# ioam3358 register map
Registers are 32-bit, access not given, no defined reset value unless marked. A register's access mark holds for its fields unless they carry their own. Addresses are absolute; registers are grouped by the start of their names; [hi:lo] are bit positions; {n}, {i} and the like mark numbered series; 'fields as' and 'values as' point back to an identical list.

## SFR
0x44E00B00 REVISION_PRM
  [7:0] REV
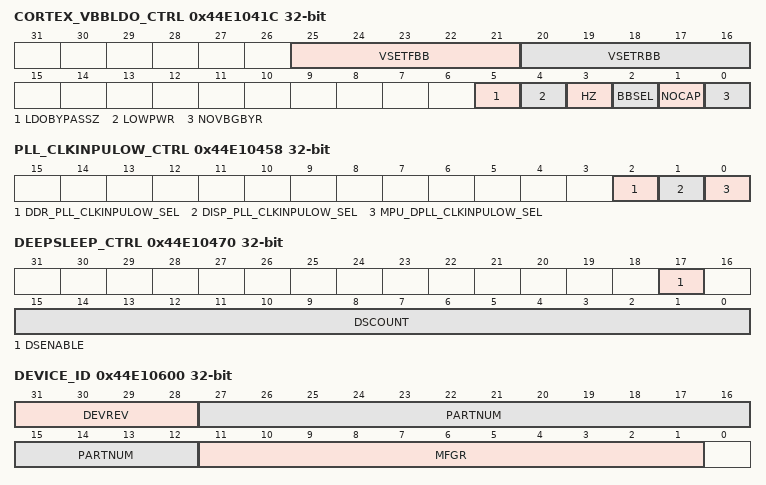
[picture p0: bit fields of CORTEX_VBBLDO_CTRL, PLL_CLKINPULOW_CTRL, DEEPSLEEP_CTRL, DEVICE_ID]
0x44E1041C CORTEX_VBBLDO_CTRL
  [25:21] VSETFBB, [20:16] VSETRBB, [5] LDOBYPASSZ, [4] LOWPWR, [3] HZ, [2] BBSEL, [1] NOCAP, [0] NOVBGBYR
0x44E10428 CORE_SLDO_CTRL
  [25:16] vset
0x44E1042C MPU_SLDO_CTRL
  [25:16] vset
0x44E10444 CLK32KDIVRATIO_CTRL
  [0] CLKDIVOPP50_EN
0x44E10458 PLL_CLKINPULOW_CTRL
  [2] DDR_PLL_CLKINPULOW_SEL, [1] DISP_PLL_CLKINPULOW_SEL, [0] MPU_DPLL_CLKINPULOW_SEL
0x44E10468 MOSC_CTRL
  [0] RESSELECT
0x44E1046C RCOSC_CTRL
  [0] STOPOSC
0x44E10470 DEEPSLEEP_CTRL
  [17] DSENABLE, [15:0] DSCOUNT
0x44E10600 DEVICE_ID
  [31:28] DEVREV, [27:12] PARTNUM, [11:1] MFGR
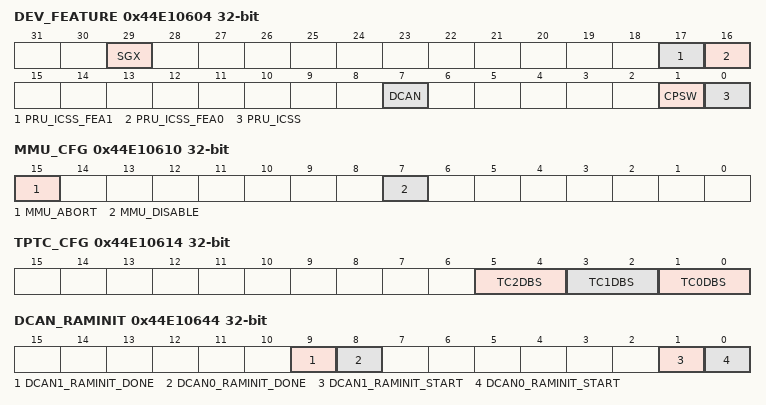
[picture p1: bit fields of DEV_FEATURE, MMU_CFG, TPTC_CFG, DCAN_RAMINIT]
0x44E10604 DEV_FEATURE
  [29] SGX, [17] PRU_ICSS_FEA1, [16] PRU_ICSS_FEA0, [7] DCAN, [1] CPSW, [0] PRU_ICSS
0x44E10610 MMU_CFG
  [15] MMU_ABORT, [7] MMU_DISABLE
0x44E10614 TPTC_CFG
  [5:4] TC2DBS, [3:2] TC1DBS, [1:0] TC0DBS
0x44E10644 DCAN_RAMINIT
  [9] DCAN1_RAMINIT_DONE, [8] DCAN0_RAMINIT_DONE, [1] DCAN1_RAMINIT_START, [0] DCAN0_RAMINIT_START
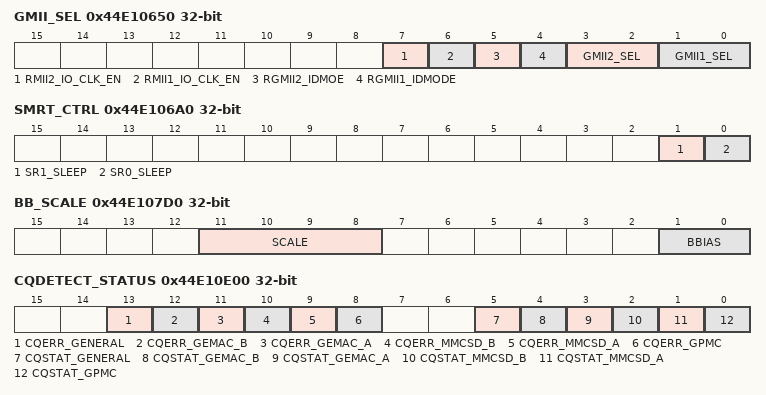
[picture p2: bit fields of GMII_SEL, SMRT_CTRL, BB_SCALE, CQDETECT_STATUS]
0x44E10650 GMII_SEL
  [7] RMII2_IO_CLK_EN, [6] RMII1_IO_CLK_EN, [5] RGMII2_IDMOE, [4] RGMII1_IDMODE, [3:2] GMII2_SEL, [1:0] GMII1_SEL
0x44E106A0 SMRT_CTRL
  [1] SR1_SLEEP, [0] SR0_SLEEP
0x44E107D0 BB_SCALE
  [11:8] SCALE, [1:0] BBIAS
0x44E10E00 CQDETECT_STATUS
  [13] CQERR_GENERAL, [12] CQERR_GEMAC_B, [11] CQERR_GEMAC_A, [10] CQERR_MMCSD_B, [9] CQERR_MMCSD_A, [8] CQERR_GPMC, [5] CQSTAT_GENERAL, [4] CQSTAT_GEMAC_B, [3] CQSTAT_GEMAC_A, [2] CQSTAT_MMCSD_B, [1] CQSTAT_MMCSD_A, [0] CQSTAT_GPMC
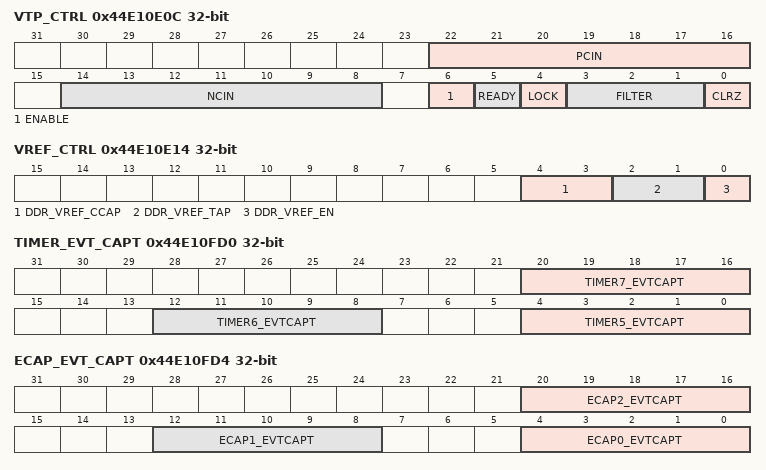
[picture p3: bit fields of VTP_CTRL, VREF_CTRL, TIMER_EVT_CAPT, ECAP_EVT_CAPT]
0x44E10E0C VTP_CTRL
  [22:16] PCIN, [14:8] NCIN, [6] ENABLE, [5] READY, [4] LOCK, [3:1] FILTER, [0] CLRZ
0x44E10E14 VREF_CTRL
  [4:3] DDR_VREF_CCAP, [2:1] DDR_VREF_TAP, [0] DDR_VREF_EN
0x44E10FD0 TIMER_EVT_CAPT
  [20:16] TIMER7_EVTCAPT, [12:8] TIMER6_EVTCAPT, [4:0] TIMER5_EVTCAPT
0x44E10FD4 ECAP_EVT_CAPT
  [20:16] ECAP2_EVTCAPT, [12:8] ECAP1_EVTCAPT, [4:0] ECAP0_EVTCAPT
0x44E10FD8 ADC_EVT_CAPT
  [3:0] ADC_EVTCAPT
0x44E11000 RESET_ISO
  [0] ISO_CONTROL
0x44E11324 M3_TXEV_EOI
  [0] M3_TXEV_EOI
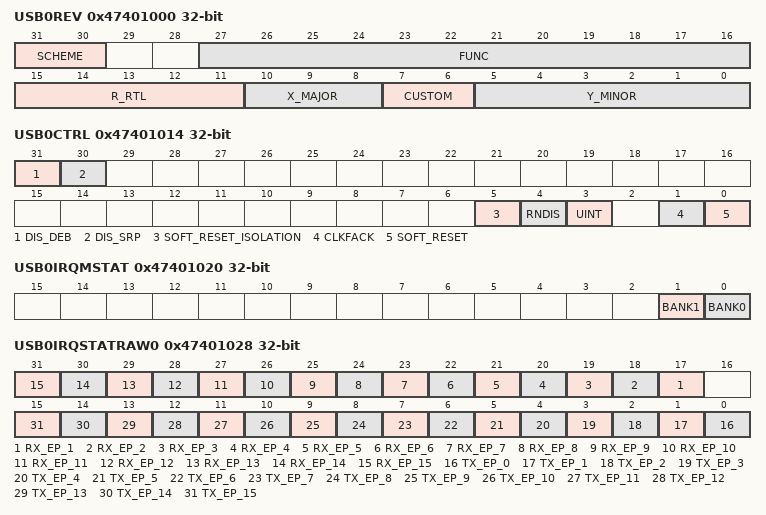
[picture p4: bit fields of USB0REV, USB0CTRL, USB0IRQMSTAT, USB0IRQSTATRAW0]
0x47401000 USB0REV
  [31:30] SCHEME, [27:16] FUNC, [15:11] R_RTL, [10:8] X_MAJOR, [7:6] CUSTOM, [5:0] Y_MINOR
0x47401014 USB0CTRL
  [31] DIS_DEB, [30] DIS_SRP, [5] SOFT_RESET_ISOLATION, [4] RNDIS, [3] UINT, [1] CLKFACK, [0] SOFT_RESET
0x47401018 USB0STAT
  [0] DRVVBUS
0x47401020 USB0IRQMSTAT
  [1] BANK1, [0] BANK0
0x47401024 USB0IRQEOI
  [0] EOI
0x47401028 USB0IRQSTATRAW0
  [n+16] RX_EP_{n} (n=1..15), [n] TX_EP_{n} (n=0..15)
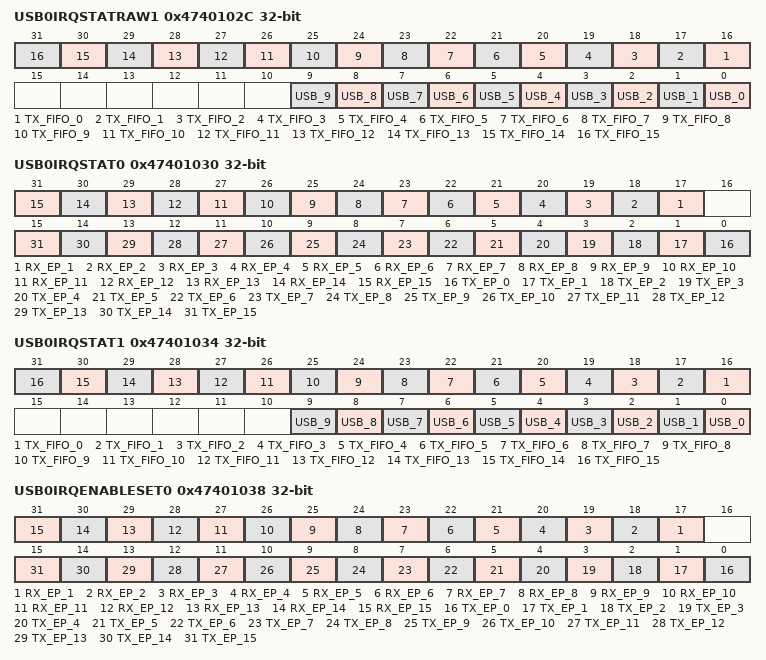
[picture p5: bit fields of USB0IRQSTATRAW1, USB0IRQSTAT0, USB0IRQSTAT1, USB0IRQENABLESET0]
0x4740102C USB0IRQSTATRAW1
  [n+16] TX_FIFO_{n} (n=0..15), [n] USB_{n} (n=0..9)
0x47401030 USB0IRQSTAT0
  [n+16] RX_EP_{n} (n=1..15), [n] TX_EP_{n} (n=0..15)
0x47401034 USB0IRQSTAT1
  [n+16] TX_FIFO_{n} (n=0..15), [n] USB_{n} (n=0..9)
0x47401038 USB0IRQENABLESET0
  [n+16] RX_EP_{n} (n=1..15), [n] TX_EP_{n} (n=0..15)
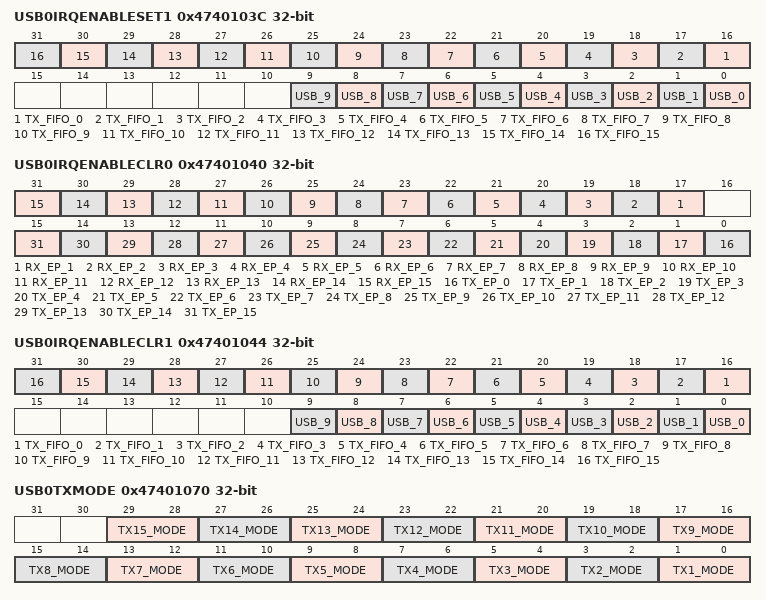
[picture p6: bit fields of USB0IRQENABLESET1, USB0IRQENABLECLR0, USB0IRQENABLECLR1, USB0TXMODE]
0x4740103C USB0IRQENABLESET1
  [n+16] TX_FIFO_{n} (n=0..15), [n] USB_{n} (n=0..9)
0x47401040 USB0IRQENABLECLR0
  [n+16] RX_EP_{n} (n=1..15), [n] TX_EP_{n} (n=0..15)
0x47401044 USB0IRQENABLECLR1
  [n+16] TX_FIFO_{n} (n=0..15), [n] USB_{n} (n=0..9)
0x47401070 USB0TXMODE
  [2n-1:2n-2] TX{n}_MODE (n=1..15)
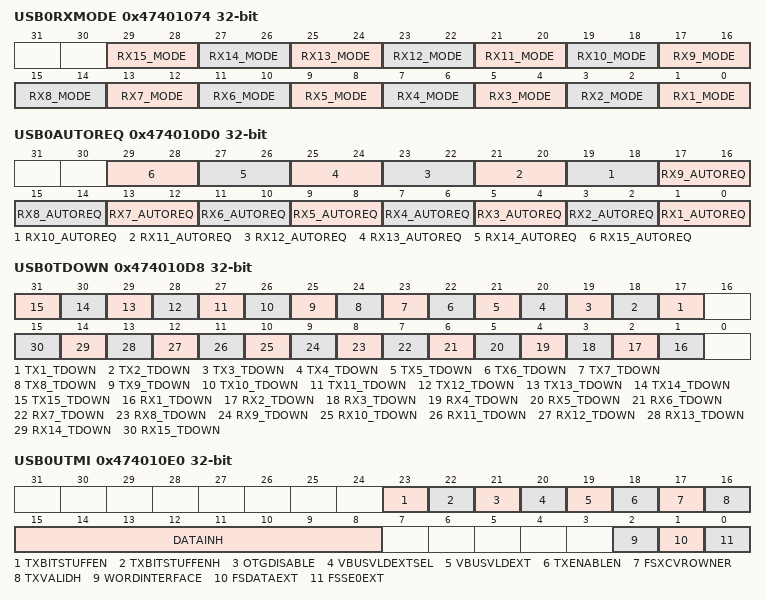
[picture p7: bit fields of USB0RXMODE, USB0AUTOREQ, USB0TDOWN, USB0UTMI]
0x47401074 USB0RXMODE
  [2n-1:2n-2] RX{n}_MODE (n=1..15)
{0x4740107C+4i} USB0GENRNDISEP{i} (i=1..15)
  [15:0] EP{i}_SIZE
0x474010D0 USB0AUTOREQ
  [2n-1:2n-2] RX{n}_AUTOREQ (n=1..15)
0x474010D4 USB0SRPFIXTIME
0x474010D8 USB0TDOWN
  [n+16] TX{n}_TDOWN (n=1..15), [n] RX{n}_TDOWN (n=1..15)
0x474010E0 USB0UTMI
  [23] TXBITSTUFFEN, [22] TXBITSTUFFENH, [21] OTGDISABLE, [20] VBUSVLDEXTSEL, [19] VBUSVLDEXT, [18] TXENABLEN, [17] FSXCVROWNER, [16] TXVALIDH, [15:8] DATAINH, [2] WORDINTERFACE, [1] FSDATAEXT, [0] FSSE0EXT
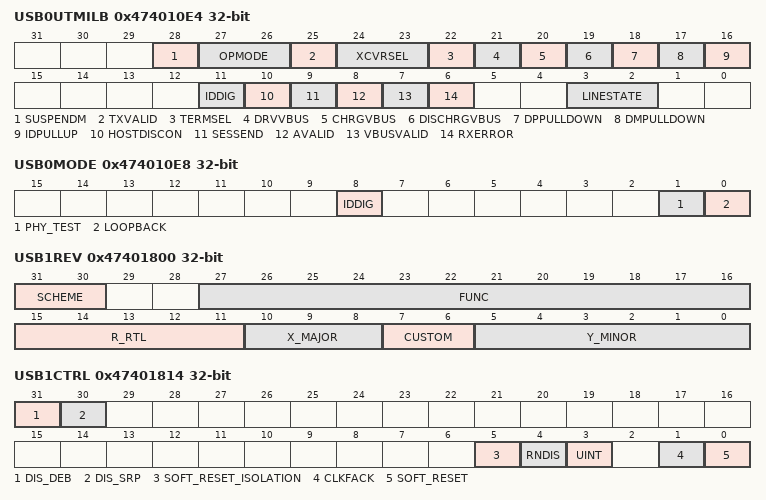
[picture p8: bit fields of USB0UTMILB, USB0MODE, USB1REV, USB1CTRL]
0x474010E4 USB0UTMILB
  [28] SUSPENDM, [27:26] OPMODE, [25] TXVALID, [24:23] XCVRSEL, [22] TERMSEL, [21] DRVVBUS, [20] CHRGVBUS, [19] DISCHRGVBUS, [18] DPPULLDOWN, [17] DMPULLDOWN, [16] IDPULLUP, [11] IDDIG, [10] HOSTDISCON, [9] SESSEND, [8] AVALID, [7] VBUSVALID, [6] RXERROR, [3:2] LINESTATE
0x474010E8 USB0MODE
  [8] IDDIG, [1] PHY_TEST, [0] LOOPBACK
0x47401800 USB1REV
  fields as USB0REV
0x47401814 USB1CTRL
  fields as USB0CTRL
0x47401818 USB1STAT
  [0] DRVVBUS
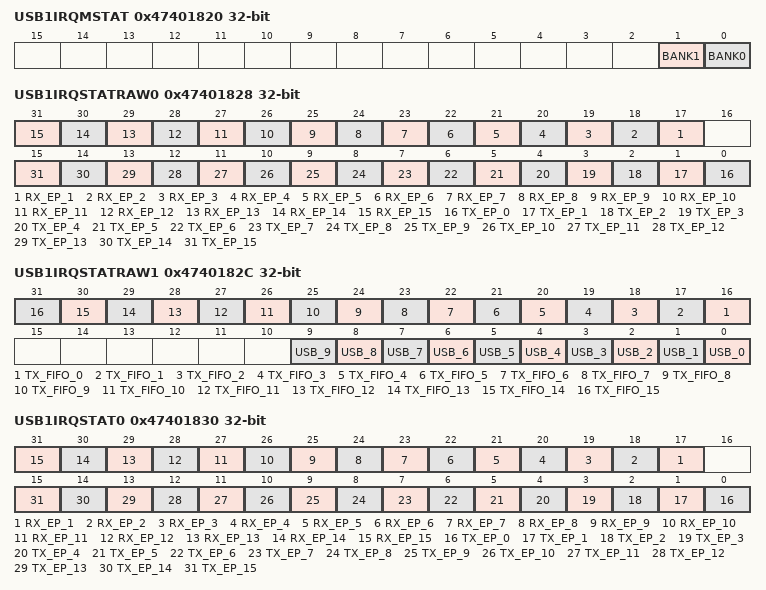
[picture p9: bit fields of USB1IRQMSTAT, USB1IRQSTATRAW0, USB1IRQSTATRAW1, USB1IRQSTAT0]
0x47401820 USB1IRQMSTAT
  [1] BANK1, [0] BANK0
0x47401824 USB1IRQEOI
  [0] EOI
0x47401828 USB1IRQSTATRAW0
  [n+16] RX_EP_{n} (n=1..15), [n] TX_EP_{n} (n=0..15)
0x4740182C USB1IRQSTATRAW1
  [n+16] TX_FIFO_{n} (n=0..15), [n] USB_{n} (n=0..9)
0x47401830 USB1IRQSTAT0
  [n+16] RX_EP_{n} (n=1..15), [n] TX_EP_{n} (n=0..15)
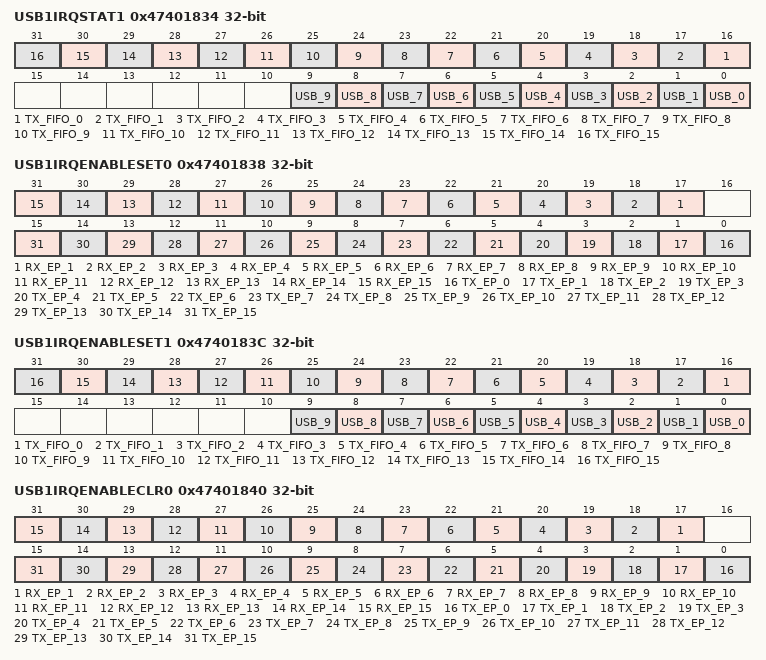
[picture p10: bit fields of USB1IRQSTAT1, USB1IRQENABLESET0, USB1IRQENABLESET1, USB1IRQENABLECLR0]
0x47401834 USB1IRQSTAT1
  [n+16] TX_FIFO_{n} (n=0..15), [n] USB_{n} (n=0..9)
0x47401838 USB1IRQENABLESET0
  [n+16] RX_EP_{n} (n=1..15), [n] TX_EP_{n} (n=0..15)
0x4740183C USB1IRQENABLESET1
  [n+16] TX_FIFO_{n} (n=0..15), [n] USB_{n} (n=0..9)
0x47401840 USB1IRQENABLECLR0
  [n+16] RX_EP_{n} (n=1..15), [n] TX_EP_{n} (n=0..15)
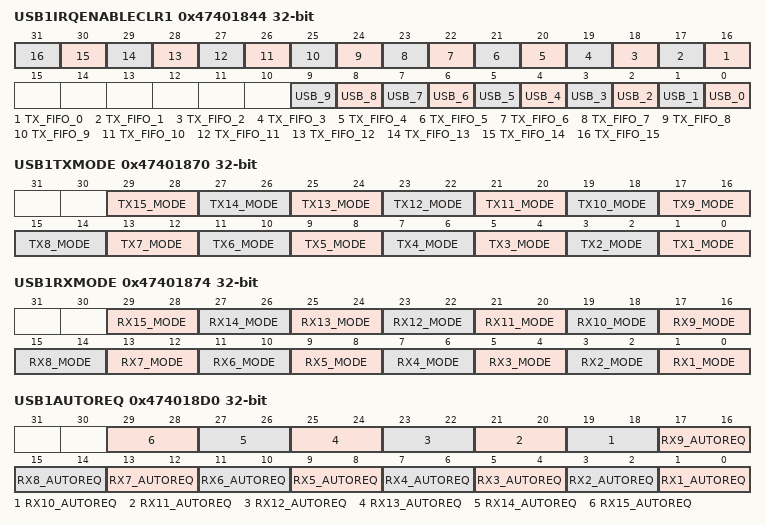
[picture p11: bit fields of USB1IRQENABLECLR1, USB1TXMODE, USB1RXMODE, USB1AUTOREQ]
0x47401844 USB1IRQENABLECLR1
  [n+16] TX_FIFO_{n} (n=0..15), [n] USB_{n} (n=0..9)
0x47401870 USB1TXMODE
  [2n-1:2n-2] TX{n}_MODE (n=1..15)
0x47401874 USB1RXMODE
  [2n-1:2n-2] RX{n}_MODE (n=1..15)
{0x4740187C+4i} USB1GENRNDISEP{i} (i=1..15)
  [15:0] EP{i}_SIZE
0x474018D0 USB1AUTOREQ
  [2n-1:2n-2] RX{n}_AUTOREQ (n=1..15)
0x474018D4 USB1SRPFIXTIME
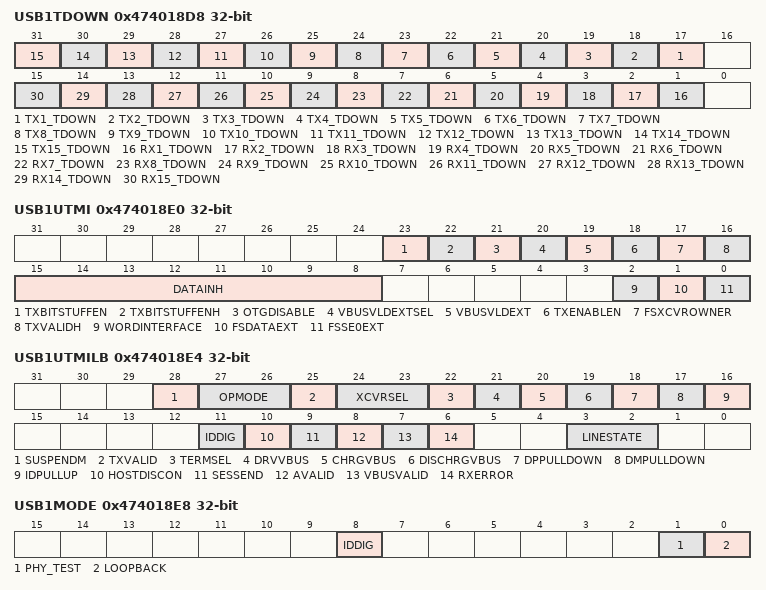
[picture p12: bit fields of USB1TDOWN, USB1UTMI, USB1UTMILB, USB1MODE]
0x474018D8 USB1TDOWN
  [n+16] TX{n}_TDOWN (n=1..15), [n] RX{n}_TDOWN (n=1..15)
0x474018E0 USB1UTMI
  fields as USB0UTMI
0x474018E4 USB1UTMILB
  fields as USB0UTMILB
0x474018E8 USB1MODE
  [8] IDDIG, [1] PHY_TEST, [0] LOOPBACK
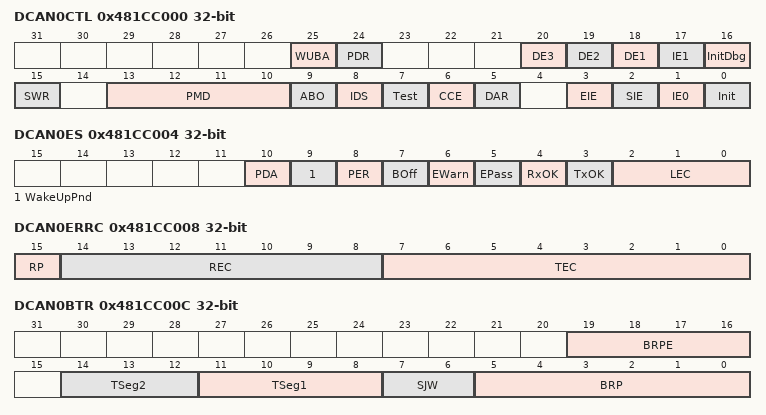
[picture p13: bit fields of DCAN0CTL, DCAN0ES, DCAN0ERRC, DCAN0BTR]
0x481CC000 DCAN0CTL
  [25] WUBA, [24] PDR, [20] DE3, [19] DE2, [18] DE1, [17] IE1, [16] InitDbg, [15] SWR, [13:10] PMD, [9] ABO, [8] IDS, [7] Test, [6] CCE, [5] DAR, [3] EIE, [2] SIE, [1] IE0, [0] Init
0x481CC004 DCAN0ES
  [10] PDA, [9] WakeUpPnd, [8] PER, [7] BOff, [6] EWarn, [5] EPass, [4] RxOK, [3] TxOK, [2:0] LEC
0x481CC004 DCAN0PARITYERR_EOI
0x481CC008 DCAN0ERRC
  [15] RP, [14:8] REC, [7:0] TEC
0x481CC00C DCAN0BTR
  [19:16] BRPE, [14:12] TSeg2, [11:8] TSeg1, [7:6] SJW, [5:0] BRP
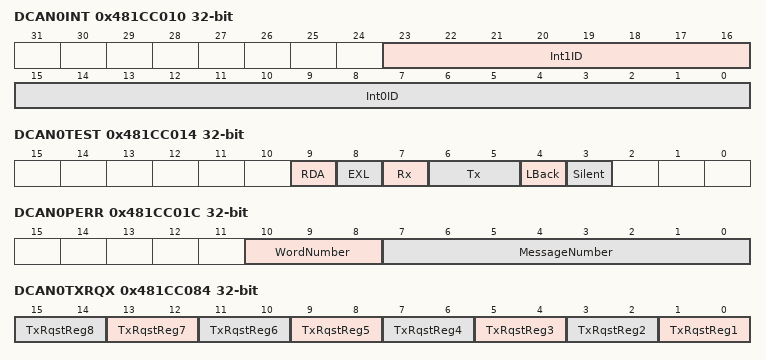
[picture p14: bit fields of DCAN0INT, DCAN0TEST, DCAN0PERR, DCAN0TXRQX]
0x481CC010 DCAN0INT
  [23:16] Int1ID, [15:0] Int0ID
0x481CC014 DCAN0TEST
  [9] RDA, [8] EXL, [7] Rx, [6:5] Tx, [4] LBack, [3] Silent
0x481CC01C DCAN0PERR
  [10:8] WordNumber, [7:0] MessageNumber
0x481CC080 DCAN0ABOTR
0x481CC084 DCAN0TXRQX
  [2n-1:2n-2] TxRqstReg{n} (n=1..8)
0x481CC088 DCAN0TXRQ12
  [n-1] TxRqst{n} (n=1..32)
0x481CC08C DCAN0TXRQ34
  [n-33] TxRqst{n} (n=33..64)
0x481CC090 DCAN0TXRQ56
  [n-65] TxRqst{n} (n=65..96)
0x481CC094 DCAN0TXRQ78
  [n-97] TxRqst{n} (n=97..128)
0x481CC098 DCAN0NWDATX
  [2n-1:2n-2] NewDatReg{n} (n=1..8)
0x481CC09C DCAN0NWDAT12
  [n-1] NewDat{n} (n=1..32)
0x481CC0A0 DCAN0NWDAT34
  [n-33] NewDat{n} (n=33..64)
0x481CC0A4 DCAN0NWDAT56
  [n-65] NewDat{n} (n=65..96)
0x481CC0A8 DCAN0NWDAT78
  [n-97] NewDat{n} (n=97..128)
0x481CC0AC DCAN0INTPNDX
  [2n-1:2n-2] IntPndReg{n} (n=1..8)
0x481CC0B0 DCAN0INTPND12
  [n-1] IntPnd{n} (n=1..32)
0x481CC0B4 DCAN0INTPND34
  [n-33] IntPnd{n} (n=33..64)
0x481CC0B8 DCAN0INTPND56
  [n-65] IntPnd{n} (n=65..96)
0x481CC0BC DCAN0INTPND78
  [n-97] IntPnd{n} (n=97..128)
0x481CC0C0 DCAN0MSGVALX
  [2n-1:2n-2] MsgValReg{n} (n=1..8)
0x481CC0C4 DCAN0MSGVAL12
  [n-1] MsgVal{n} (n=1..32)
0x481CC0C8 DCAN0MSGVAL34
  [n-33] MsgVal{n} (n=33..64)
0x481CC0CC DCAN0MSGVAL56
  [n-65] MsgVal{n} (n=65..96)
0x481CC0D0 DCAN0MSGVAL78
  [n-97] MsgVal{n} (n=97..128)
0x481CC0D8 DCAN0INTMUX12
  [n-1] IntMux{n} (n=1..32)
0x481CC0DC DCAN0INTMUX34
  [n-33] IntMux{n} (n=33..64)
0x481CC0E0 DCAN0INTMUX56
  [n-65] IntMux{n} (n=65..96)
0x481CC0E4 DCAN0INTMUX78
  [n-97] IntMux{n} (n=97..128)
0x481CC100 DCAN0IF1CMD
  [23] WR_RD, [22] Mask, [21] Arb, [20] Control, [19] ClrIntPnd, [18] TxRqst_NewDat, [17] DataA, [16] DataB, [15] Busy, [14] DMAactive, [7:0] MessageNumber
{0x481CC0E4+0x20*i} DCAN0IF{i}MSK (i=1..3)
  [31] MXtd, [30] MDir, [n] Msk{n} (n=0..28)
{0x481CC0E8+0x20*i} DCAN0IF{i}ARB (i=1..3)
  [31] MsgVal, [30] Xtd, [29] Dir, [n] ID{n} (n=0..28)
{0x481CC0EC+0x20*i} DCAN0IF{i}MCTL (i=1..3)
  [15] NewDat, [14] MsgLst, [13] IntPnd, [12] UMask, [11] TxIE, [10] RxIE, [9] RmtEn, [8] TxRqst, [7] EoB, [3:0] DLC
{0x481CC0F0+0x20*i} DCAN0IF{i}DATA (i=1..3)
  [8n+7:8n] Data{n} (n=0..3)
{0x481CC0F4+0x20*i} DCAN0IF{i}DATB (i=1..3)
  [8n-25:8n-32] Data{n} (n=4..7)
0x481CC120 DCAN0IF2CMD
  fields as DCAN0IF1CMD
0x481CC140 DCAN0IF3OBS
  [15] IF3_Upd, [12] IF3_SDB, [11] IF3_SDA, [10] IF3_SC, [9] IF3_SA, [8] IF3_SM, [4] DataB, [3] DataA, [2] Ctrl, [1] Arb, [0] Mask
0x481CC160 DCAN0IF3UPD12
  [n-1] IF3UpdEn{n} (n=1..32)
0x481CC164 DCAN0IF3UPD34
  [n-33] IF3UpdEn{n} (n=33..64)
0x481CC168 DCAN0IF3UPD56
  [n-65] IF3UpdEn{n} (n=65..96)
0x481CC16C DCAN0IF3UPD78
  [n-97] IF3UpdEn{n} (n=97..128)
0x481CC1E0 DCAN0TIOC
  [18] PU, [17] PD, [16] OD, [3] Func, [2] Dir, [1] Out, [0] In
0x481CC1E4 DCAN0RIOC
  [18] PU, [17] PD, [16] OD, [3] Func, [2] Dir, [1] Out, [0] In
0x481D0000 DCAN1CTL
  fields as DCAN0CTL
0x481D0004 DCAN1ES
  fields as DCAN0ES
0x481D0004 DCAN1PARITYERR_EOI
0x481D0008 DCAN1ERRC
  [15] RP, [14:8] REC, [7:0] TEC
0x481D000C DCAN1BTR
  [19:16] BRPE, [14:12] TSeg2, [11:8] TSeg1, [7:6] SJW, [5:0] BRP
0x481D0010 DCAN1INT
  [23:16] Int1ID, [15:0] Int0ID
0x481D0014 DCAN1TEST
  [9] RDA, [8] EXL, [7] Rx, [6:5] Tx, [4] LBack, [3] Silent
0x481D001C DCAN1PERR
  [10:8] WordNumber, [7:0] MessageNumber
0x481D0080 DCAN1ABOTR
0x481D0084 DCAN1TXRQX
  [2n-1:2n-2] TxRqstReg{n} (n=1..8)
0x481D0088 DCAN1TXRQ12
  [n-1] TxRqst{n} (n=1..32)
0x481D008C DCAN1TXRQ34
  [n-33] TxRqst{n} (n=33..64)
0x481D0090 DCAN1TXRQ56
  [n-65] TxRqst{n} (n=65..96)
0x481D0094 DCAN1TXRQ78
  [n-97] TxRqst{n} (n=97..128)
0x481D0098 DCAN1NWDATX
  [2n-1:2n-2] NewDatReg{n} (n=1..8)
0x481D009C DCAN1NWDAT12
  [n-1] NewDat{n} (n=1..32)
0x481D00A0 DCAN1NWDAT34
  [n-33] NewDat{n} (n=33..64)
0x481D00A4 DCAN1NWDAT56
  [n-65] NewDat{n} (n=65..96)
0x481D00A8 DCAN1NWDAT78
  [n-97] NewDat{n} (n=97..128)
0x481D00AC DCAN1INTPNDX
  [2n-1:2n-2] IntPndReg{n} (n=1..8)
0x481D00B0 DCAN1INTPND12
  [n-1] IntPnd{n} (n=1..32)
0x481D00B4 DCAN1INTPND34
  [n-33] IntPnd{n} (n=33..64)
0x481D00B8 DCAN1INTPND56
  [n-65] IntPnd{n} (n=65..96)
0x481D00BC DCAN1INTPND78
  [n-97] IntPnd{n} (n=97..128)
0x481D00C0 DCAN1MSGVALX
  [2n-1:2n-2] MsgValReg{n} (n=1..8)
0x481D00C4 DCAN1MSGVAL12
  [n-1] MsgVal{n} (n=1..32)
0x481D00C8 DCAN1MSGVAL34
  [n-33] MsgVal{n} (n=33..64)
0x481D00CC DCAN1MSGVAL56
  [n-65] MsgVal{n} (n=65..96)
0x481D00D0 DCAN1MSGVAL78
  [n-97] MsgVal{n} (n=97..128)
0x481D00D8 DCAN1INTMUX12
  [n-1] IntMux{n} (n=1..32)
0x481D00DC DCAN1INTMUX34
  [n-33] IntMux{n} (n=33..64)
0x481D00E0 DCAN1INTMUX56
  [n-65] IntMux{n} (n=65..96)
0x481D00E4 DCAN1INTMUX78
  [n-97] IntMux{n} (n=97..128)
0x481D0100 DCAN1IF1CMD
  fields as DCAN0IF1CMD
{0x481D00E4+0x20*i} DCAN1IF{i}MSK (i=1..3)
  [31] MXtd, [30] MDir, [n] Msk{n} (n=0..28)
{0x481D00E8+0x20*i} DCAN1IF{i}ARB (i=1..3)
  [31] MsgVal, [30] Xtd, [29] Dir, [n] ID{n} (n=0..28)
{0x481D00EC+0x20*i} DCAN1IF{i}MCTL (i=1..3)
  fields as DCAN0IF1MCTL
{0x481D00F0+0x20*i} DCAN1IF{i}DATA (i=1..3)
  [8n+7:8n] Data{n} (n=0..3)
{0x481D00F4+0x20*i} DCAN1IF{i}DATB (i=1..3)
  [8n-25:8n-32] Data{n} (n=4..7)
0x481D0120 DCAN1IF2CMD
  fields as DCAN0IF1CMD
0x481D0140 DCAN1IF3OBS
  fields as DCAN0IF3OBS
0x481D0160 DCAN1IF3UPD12
  [n-1] IF3UpdEn{n} (n=1..32)
0x481D0164 DCAN1IF3UPD34
  [n-33] IF3UpdEn{n} (n=33..64)
0x481D0168 DCAN1IF3UPD56
  [n-65] IF3UpdEn{n} (n=65..96)
0x481D016C DCAN1IF3UPD78
  [n-97] IF3UpdEn{n} (n=97..128)
0x481D01E0 DCAN1TIOC
  [18] PU, [17] PD, [16] OD, [3] Func, [2] Dir, [1] Out, [0] In
0x481D01E4 DCAN1RIOC
  [18] PU, [17] PD, [16] OD, [3] Func, [2] Dir, [1] Out, [0] In
